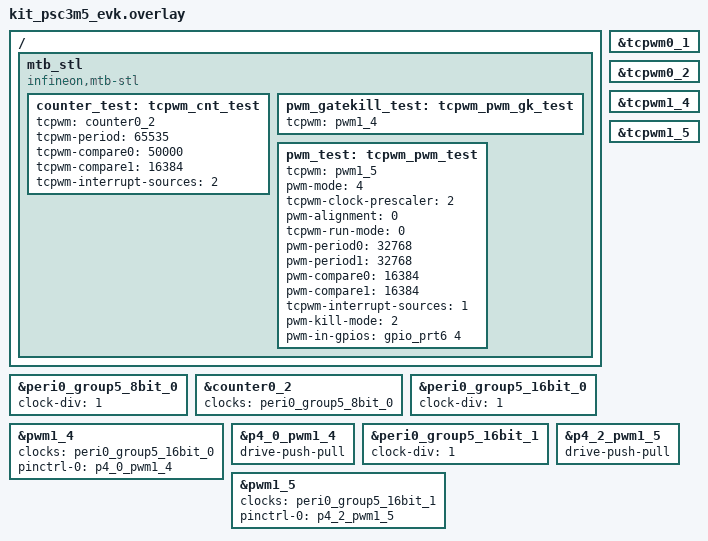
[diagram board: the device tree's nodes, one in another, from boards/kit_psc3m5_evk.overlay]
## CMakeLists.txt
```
# SPDX-License-Identifier: Apache-2.0

cmake_minimum_required(VERSION 3.20.0)

find_package(Zephyr REQUIRED HINTS $ENV{ZEPHYR_BASE})
project(post-tcpwm-test-mtb-stl)

target_sources(app PRIVATE src/main.c)
```

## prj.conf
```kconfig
# SPDX-FileCopyrightText: Copyright (c) 2026 Infineon Technologies AG,
# SPDX-FileCopyrightText: or an affiliate of Infineon Technologies AG. All rights reserved.
#
# SPDX-License-Identifier: Apache-2.0

# POST subsystem
CONFIG_POST=y
CONFIG_POST_VENDOR_MTB_STL=y
CONFIG_POST_SHELL=y
CONFIG_POST_HALT_ON_FAILURE=n
CONFIG_POST_RUNTIME_TESTS=y

# Shell support
CONFIG_SHELL=y

# Logging
CONFIG_LOG=y
CONFIG_POST_LOG_LEVEL=4

# Shared interrupts
# Note: This config is enabled by default.
# This config enables to have multiple ISR for same irq line,
# since both test and drivers use same irq line
CONFIG_SHARED_INTERRUPTS=y
```

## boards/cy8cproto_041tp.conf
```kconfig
# SPDX-FileCopyrightText: Copyright (c) 2026 Infineon Technologies AG,
# SPDX-FileCopyrightText: or an affiliate of Infineon Technologies AG. All rights reserved.
#
# SPDX-License-Identifier: Apache-2.0

# Enable MTB-STL tests
CONFIG_POST_MTB_STL_COUNTER=y
CONFIG_POST_MTB_STL_PWM=y
CONFIG_POST_MTB_STL_PWM_GATEKILL=y

# Zephyr driver configs
CONFIG_COUNTER=y
CONFIG_PWM=y
```

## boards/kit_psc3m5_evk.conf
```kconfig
# SPDX-FileCopyrightText: Copyright (c) 2026 Infineon Technologies AG,
# SPDX-FileCopyrightText: or an affiliate of Infineon Technologies AG. All rights reserved.
#
# SPDX-License-Identifier: Apache-2.0

# Enable MTB-STL tests
CONFIG_POST_MTB_STL_COUNTER=y
CONFIG_POST_MTB_STL_PWM=y
CONFIG_POST_MTB_STL_PWM_GATEKILL=y

# Zephyr driver configs
CONFIG_COUNTER=y
CONFIG_PWM=y
CONFIG_DYNAMIC_INTERRUPTS=y
```

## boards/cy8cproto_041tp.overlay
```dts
/*
 * SPDX-FileCopyrightText: Copyright (c) 2026 Infineon Technologies AG,
 * SPDX-FileCopyrightText: or an affiliate of Infineon Technologies AG. All rights reserved.
 *
 * SPDX-License-Identifier: Apache-2.0
 */

/*
 * Clock dividers for TCPWM test peripherals
 */

&peri_clk_div6 {
	status = "okay";
	clock-div = <1>;
	/* Counter test: divider 6 -> TCPWM counter 2, no prescale */
};

&peri_clk_div7 {
	status = "okay";
	clock-div = <1>;
	/* PWM gatekill test: divider 7 -> TCPWM PWM 4, no prescale */
};

&peri_clk_div8 {
	status = "okay";
	clock-div = <1>;
	/* PWM test: divider 8 -> TCPWM PWM 3 */
};

/*
 * Enable TCPWM instances and assign clock dividers
 */

&tcpwm0_2 {
	status = "okay";
};

&counter0_2 {
	status = "okay";
	clocks = <&peri_clk_div6>;
};

&tcpwm0_4 {
	status = "okay";
};

&pwm0_4 {
	status = "okay";
	clocks = <&peri_clk_div7>;
	pinctrl-0 = <&p2_4_pwm0_4>;
	pinctrl-names = "default";
};

&tcpwm0_3 {
	status = "okay";
};

&pwm0_3 {
	compatible = "infineon,tcpwm-pwm";
	status = "okay";
	clocks = <&peri_clk_div8>;
	pinctrl-0 = <&p2_2_pwm0_3>;
	pinctrl-names = "default";
};

&p2_2_pwm0_3 {
	status = "okay";
	drive-push-pull;
};

&gpio_prt2 {
	status = "okay";
};

/ {
	mtb_stl: mtb_stl {
		compatible = "infineon,mtb-stl";
		status = "okay";

		/*
		 * PWM test to check the duty cycle is achieved in o/p
		 */
		pwm_test: tcpwm_pwm_test {
			tcpwm = <&pwm0_3>;
			pwm-mode = <4>;
			tcpwm-clock-prescaler = <0>;
			pwm-alignment = <0>;
			tcpwm-run-mode = <0>;
			pwm-period0 = <32768>;
			pwm-period1 = <32768>;
			pwm-compare0 = <16384>;
			pwm-compare1 = <16384>;
			tcpwm-interrupt-sources = <1>;
			pwm-kill-mode = <2>;
			pwm-in-gpios = <&gpio_prt2 3 GPIO_ACTIVE_HIGH>;
		};

		/*
		 * Counter self-test: TCPWM counter 2 verifies correct
		 * counting and compare-match interrupt generation.
		 *
		 * Clock: counter0_2 -> peri_clk_div6 (assigned above)
		 * IRQ: inherited from parent tcpwm0_2 (IRQ 18)
		 */
		counter_test: tcpwm_cnt_test {
			tcpwm = <&counter0_2>;
			tcpwm-period = <32768>;
			tcpwm-compare0 = <16384>;
			tcpwm-compare1 = <16384>;
			tcpwm-interrupt-sources = <2>;
		};

		/*
		 * PWM gate/kill test: TCPWM PWM 4 verifies that the
		 * kill mechanism correctly stops PWM output.
		 *
		 * Clock: pwm0_4 -> peri_clk_div7 (assigned above)
		 */
		pwm_gatekill_test: tcpwm_pwm_gk_test {
			tcpwm = <&pwm0_4>;
		};
	};
};
```

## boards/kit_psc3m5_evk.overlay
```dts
/*
 * SPDX-FileCopyrightText: Copyright (c) 2026 Infineon Technologies AG,
 * SPDX-FileCopyrightText: or an affiliate of Infineon Technologies AG. All rights reserved.
 *
 * SPDX-License-Identifier: Apache-2.0
 */

#include <zephyr/dt-bindings/gpio/gpio.h>

&tcpwm0_1 {
	status = "okay";
};

&peri0_group5_8bit_0 {
	status = "okay";
	clock-div = <1>;
};

&tcpwm0_2 {
	status = "okay";
};

&counter0_2 {
	status = "okay";
	clocks = <&peri0_group5_8bit_0>;
};

&peri0_group5_16bit_0 {
	status = "okay";
	clock-div = <1>;
};

&tcpwm1_4 {
	status = "okay";
};

&pwm1_4 {
	status = "okay";
	clocks = <&peri0_group5_16bit_0>;
	pinctrl-0 = <&p4_0_pwm1_4>;
	pinctrl-names = "default";
};

&p4_0_pwm1_4 {
	drive-push-pull;
};

&peri0_group5_16bit_1 {
	status = "okay";
	clock-div = <1>;
};

&tcpwm1_5 {
	status = "okay";
};

&pwm1_5 {
	status = "okay";
	clocks = <&peri0_group5_16bit_1>;
	pinctrl-0 = <&p4_2_pwm1_5>;
	pinctrl-names = "default";
};

&p4_2_pwm1_5 {
	drive-push-pull;
};

/ {
	mtb_stl: mtb_stl {
		compatible = "infineon,mtb-stl";
		status = "okay";

		counter_test: tcpwm_cnt_test {
			tcpwm = <&counter0_2>;
			tcpwm-period = <65535>;
			tcpwm-compare0 = <50000>;
			tcpwm-compare1 = <16384>;
			tcpwm-interrupt-sources = <2>;
		};

		pwm_gatekill_test: tcpwm_pwm_gk_test {
			tcpwm = <&pwm1_4>;
		};

		pwm_test: tcpwm_pwm_test {
			tcpwm = <&pwm1_5>;
			pwm-mode = <4>;
			tcpwm-clock-prescaler = <2>;
			pwm-alignment = <0>;
			tcpwm-run-mode = <0>;
			pwm-period0 = <32768>;
			pwm-period1 = <32768>;
			pwm-compare0 = <16384>;
			pwm-compare1 = <16384>;
			tcpwm-interrupt-sources = <1>;
			pwm-kill-mode = <2>;
			pwm-in-gpios = <&gpio_prt6 4 GPIO_ACTIVE_HIGH>;
		};
	};
};
```

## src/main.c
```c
/*
 * SPDX-FileCopyrightText: Copyright (c) 2026 Infineon Technologies AG,
 * SPDX-FileCopyrightText: or an affiliate of Infineon Technologies AG. All rights reserved.
 *
 * SPDX-License-Identifier: Apache-2.0
 */

#include <zephyr/kernel.h>
#include <zephyr/post/post.h>
#include <zephyr/shell/shell.h>
#include <zephyr/logging/log.h>

LOG_MODULE_REGISTER(post_sample, LOG_LEVEL_INF);

int main(void)
{
	uint32_t passed;
	uint32_t failed;
	uint32_t skipped;

	printk("\n");
	printk("====================================\n");
	printk("Starting POST TCPWM sample application\n");
	printk("====================================\n");
	printk("\n");

	LOG_INF("POST subsystem initialized");
	LOG_INF("MTB-STL tests registered during boot");

	post_get_summary(&passed, &failed, &skipped);
	printk("POST summary: %u passed, %u failed, %u skipped\n", passed, failed, skipped);

	printk("Available shell commands:\n");
	printk("  post list   - List all registered POST tests\n");
	printk("  post run    - Run runtime POST tests\n");
	printk("  post status - Show POST test results\n");
	printk("\n");

	/* Application main loop */
	while (1) {
		k_sleep(K_SECONDS(5));
		LOG_DBG("Application running...");
	}

	return 0;
}
```
